# CH32H417 register map
Vendor: WCH Ltd.; File version: 1.2
Registers are 32-bit, read-write, reset 0x0 unless marked. A register's access mark holds for its fields unless they carry their own. Offsets are from the block's base; [hi:lo] are bit positions; lines under a group give offsets from that group; 'fields as' and 'values as' point back to an identical list.

## DFSDM — Digital filter for sigma delta modulators
Base 0x40017000
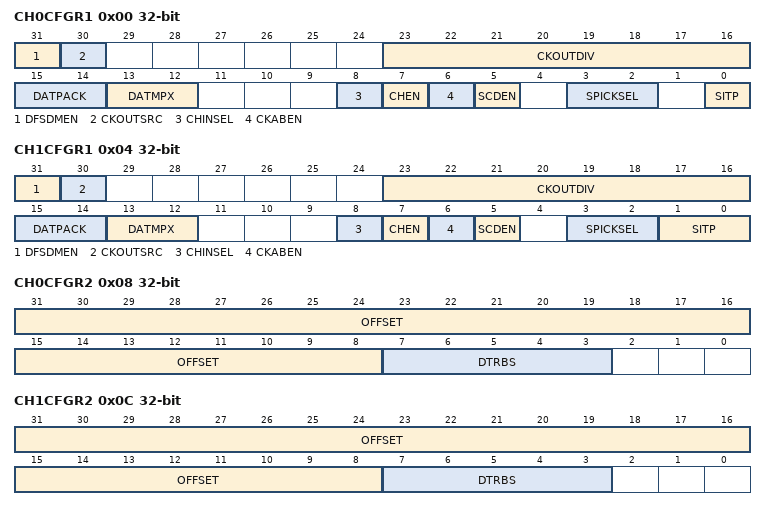
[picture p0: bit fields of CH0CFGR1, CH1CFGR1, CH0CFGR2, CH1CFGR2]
0x00 CH0CFGR1 — channel configuration 0 register
  [31] DFSDMEN — The DFSDM interface is globally enabled
  [30] CKOUTSRC — Output Serial Clock Source Selection
  [23:16] CKOUTDIV — Output Serial Clock Divider
  [15:14] DATPACK — R32_DFSDM_CHyDATINR register data encapsulation mode
  [13:12] DATMPX — Channel 0 Input Data Multiplexer
  [8] CHINSEL — Channel Input Selection
  [7] CHEN — Channel 0 enables
  [6] CKABEN — Channel 0 Clock Missing Detector Enables
  [5] SCDEN — Channel 0 Short Circuit Detector Enables
  [3:2] SPICKSEL — Channel 0 SPI Clock Selection
  [0] SITP — Channel 0 Serial Interface Type
0x04 CH1CFGR1 — channel configuration 1 register
  [31] DFSDMEN — The DFSDM interface is globally enabled
  [30] CKOUTSRC — Output Serial Clock Source Selection
  [23:16] CKOUTDIV — Output Serial Clock Divider
  [15:14] DATPACK — R32_DFSDM_CHyDATINR register data encapsulation mode
  [13:12] DATMPX — Channel 1 Input Data Multiplexer
  [8] CHINSEL — Channel Input Selection
  [7] CHEN — Channel 1 enables
  [6] CKABEN — Channel 1 Clock Missing Detector Enables
  [5] SCDEN — Channel 1 Short Circuit Detector Enables
  [3:2] SPICKSEL — Channel 1 SPI Clock Selection
  [1:0] SITP — Channel 1 Serial Interface Type
0x08 CH0CFGR2 — channel configuration 0 register
  [31:8] OFFSET — Channel 0 24-bit calibration offset
  [7:3] DTRBS — Channel 0 data right shift
0x0C CH1CFGR2 — channel configuration 1 register
  [31:8] OFFSET — Channel 1 24-bit calibration offset
  [7:3] DTRBS — Channel 1 data right shift
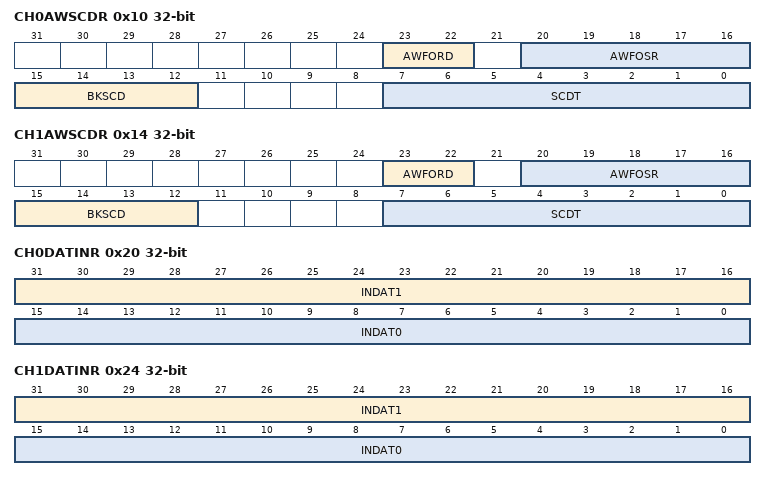
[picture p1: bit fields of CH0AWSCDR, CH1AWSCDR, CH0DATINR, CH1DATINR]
0x10 CH0AWSCDR — analog watchdog and short-circuit detector register
  [23:22] AWFORD — Channel 0 analog watchdog Sinc filter order
  [20:16] AWFOSR — Channel 0 analog watchdog filter oversampling rate
  [15:12] BKSCD — Channel 0 Short Circuit Detector Open Signal Distribution
  [7:0] SCDT — Short Circuit Detector Threshold for Channel 0
0x14 CH1AWSCDR — analog watchdog and short-circuit detector register
  [23:22] AWFORD — Channel 1 analog watchdog Sinc filter order
  [20:16] AWFOSR — Channel 1 analog watchdog filter oversampling rate
  [15:12] BKSCD — Channel 1 Short Circuit Detector Open Signal Distribution
  [7:0] SCDT — Short Circuit Detector Threshold for Channel 1
0x18 CH0WDATR — channel watchdog filter data register
  [15:0] WDATA — Enter channel 0 watchdog data
0x1C CH1WDATR — channel watchdog filter data register
  [15:0] WDATA — Enter channel 1 watchdog data
0x20 CH0DATINR — channel data input register
  [31:16] INDAT1 — Input data for channel y or channel y+1
  [15:0] INDAT0 — Channel Y Input Data
0x24 CH1DATINR — channel data input register
  [31:16] INDAT1 — Input data for channel 1 or channel 2
  [15:0] INDAT0 — Channel 1 Input Data
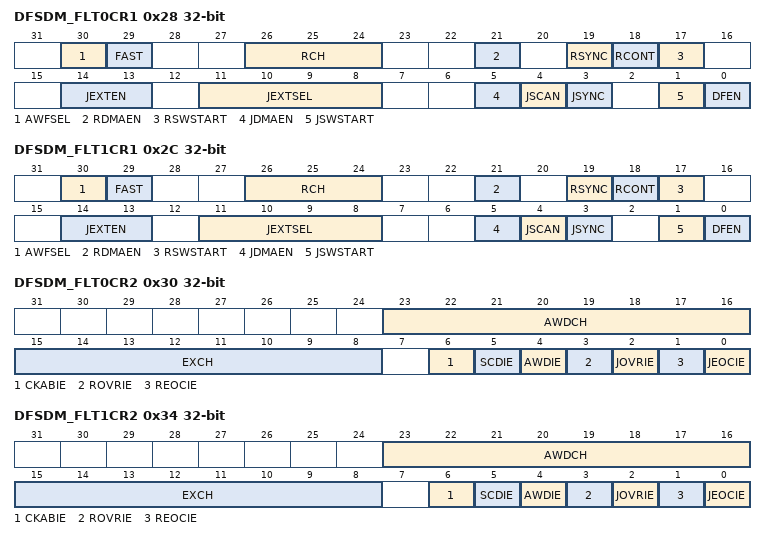
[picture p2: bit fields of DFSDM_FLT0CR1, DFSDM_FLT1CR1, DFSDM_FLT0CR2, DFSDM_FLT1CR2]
0x28 DFSDM_FLT0CR1 — control register 1
  [30] AWFSEL — Analog watchdog fast mode select
  [29] FAST — Fast conversion mode selection for regular conversions
  [26:24] RCH — Regular channel selection
  [21] RDMAEN — DMA channel enabled to read data for the regular conversion
  [19] RSYNC — Launch regular conversion synchronously with DFSDM0
  [18] RCONT — Continuous mode selection for regular conversions
  [17] RSWSTART — Software start of a conversion on the regular channel
  [14:13] JEXTEN — Trigger enable and trigger edge selection for injected conversions
  [11:8] JEXTSEL — Trigger signal selection for launching injected conversions
  [5] JDMAEN — DMA channel enabled to read data for the injected channel group
  [4] JSCAN — Scanning conversion mode for injected conversions
  [3] JSYNC — Launch an injected conversion synchronously with the DFSDM0 JSWSTART trigger
  [1] JSWSTART — Start a conversion of the injected group of channels
  [0] DFEN — DFSDM enable
0x2C DFSDM_FLT1CR1 — control register 1
  fields as DFSDM_FLT0CR1
0x30 DFSDM_FLT0CR2 — control register 2
  [23:16] AWDCH — Analog watchdog channel selection
  [15:8] EXCH — Extremes detector channel selection
  [6] CKABIE — Clock absence interrupt enable
  [5] SCDIE — Short-circuit detector interrupt enable
  [4] AWDIE — Analog watchdog interrupt enable
  [3] ROVRIE — Regular data overrun interrupt enable
  [2] JOVRIE — Injected data overrun interrupt enable
  [1] REOCIE — Regular end of conversion interrupt enable
  [0] JEOCIE — Injected end of conversion interrupt enable
0x34 DFSDM_FLT1CR2 — control register 2
  fields as DFSDM_FLT0CR2
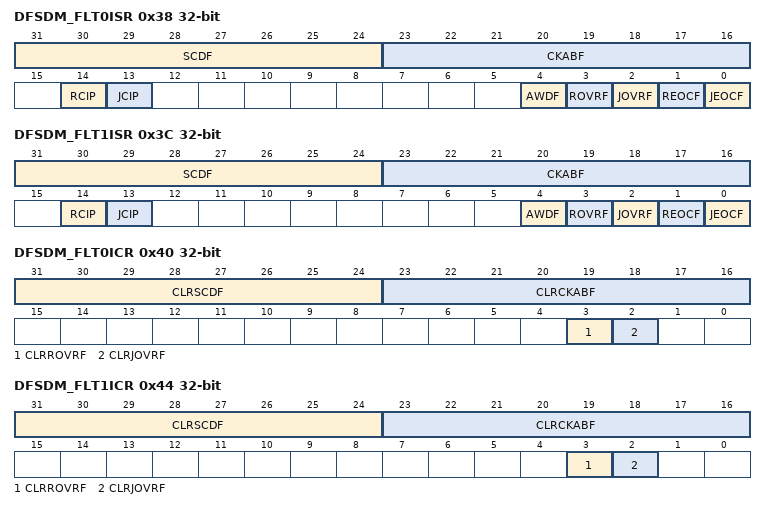
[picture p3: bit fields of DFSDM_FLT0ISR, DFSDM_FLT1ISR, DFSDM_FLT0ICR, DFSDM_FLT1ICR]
0x38 DFSDM_FLT0ISR ro — interrupt and status register
  [31:24] SCDF — short-circuit detector flag
  [23:16] CKABF — Clock absence flag
  [14] RCIP — Regular conversion in progress status
  [13] JCIP — Injected conversion in progress status
  [4] AWDF — Analog watchdog
  [3] ROVRF — Regular conversion overrun flag
  [2] JOVRF — Injected conversion overrun flag
  [1] REOCF — End of regular conversion flag
  [0] JEOCF — End of injected conversion flag
0x3C DFSDM_FLT1ISR ro — interrupt and status register
  fields as DFSDM_FLT0ISR
0x40 DFSDM_FLT0ICR — interrupt flag clear register
  [31:24] CLRSCDF — Clear the short-circuit detector flag
  [23:16] CLRCKABF — Clear the clock absence flag
  [3] CLRROVRF — Clear the regular conversion overrun flag
  [2] CLRJOVRF — Clear the injected conversion overrun flag
0x44 DFSDM_FLT1ICR — interrupt flag clear register
  fields as DFSDM_FLT0ICR
0x48 DFSDM_FLT0JCHGR reset 0x1 — injected channel group selection register
  [1:0] JCHG — Injected channel group selection
0x4C DFSDM_FLT1JCHGR reset 0x1 — injected channel group selection register
  [1:0] JCHG — Injected channel group selection
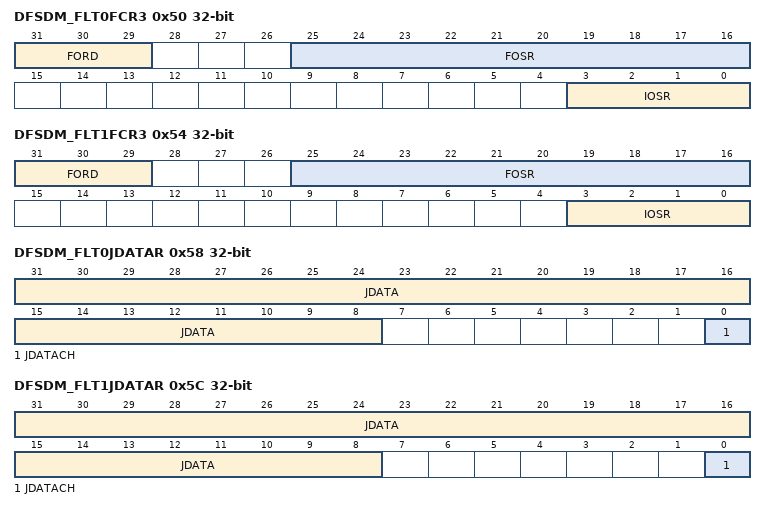
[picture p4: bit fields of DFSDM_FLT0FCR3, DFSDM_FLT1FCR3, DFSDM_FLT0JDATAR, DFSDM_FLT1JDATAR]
0x50 DFSDM_FLT0FCR3 access per field — control register 3
  [31:29] FORD ro — Sinc Filter Order
  [25:16] FOSR rw — Sinc filter oversampling rate
  [3:0] IOSR rw — The integrator oversampling rate is 2 to the power of IOSR
0x54 DFSDM_FLT1FCR3 access per field — control register 3
  fields as DFSDM_FLT0FCR3
0x58 DFSDM_FLT0JDATAR ro — data register for injected group
  [31:8] JDATA — Injected group conversion data
  [0] JDATACH — Injected channel most recently converted
0x5C DFSDM_FLT1JDATAR ro — data register for injected group
  fields as DFSDM_FLT0JDATAR
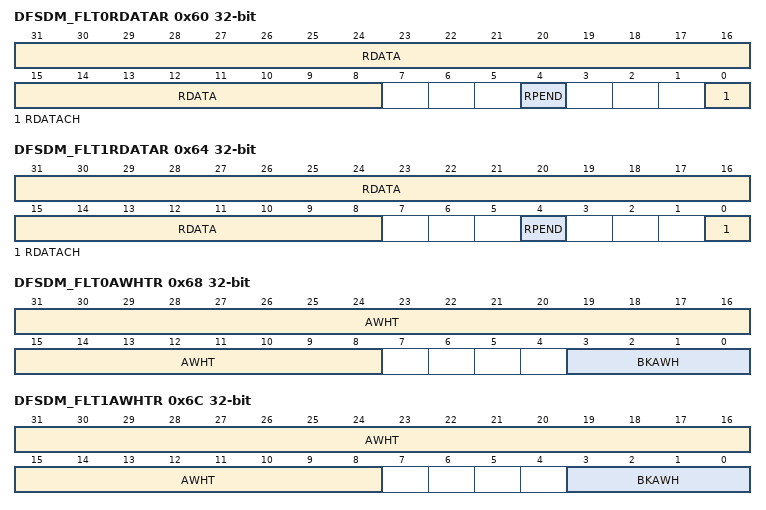
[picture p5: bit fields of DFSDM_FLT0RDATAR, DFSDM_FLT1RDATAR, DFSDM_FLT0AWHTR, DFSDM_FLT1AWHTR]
0x60 DFSDM_FLT0RDATAR ro — data register for the regular channel
  [31:8] RDATA — Regular channel conversion data
  [4] RPEND — Regular channel pending data
  [0] RDATACH — Regular channel most recently converted
0x64 DFSDM_FLT1RDATAR ro — data register for the regular channel
  fields as DFSDM_FLT0RDATAR
0x68 DFSDM_FLT0AWHTR — analog watchdog high threshold register
  [31:8] AWHT — Analog watchdog high threshold
  [3:0] BKAWH — Break signal assignment to analog watchdog high threshold event
0x6C DFSDM_FLT1AWHTR — analog watchdog high threshold register
  fields as DFSDM_FLT0AWHTR
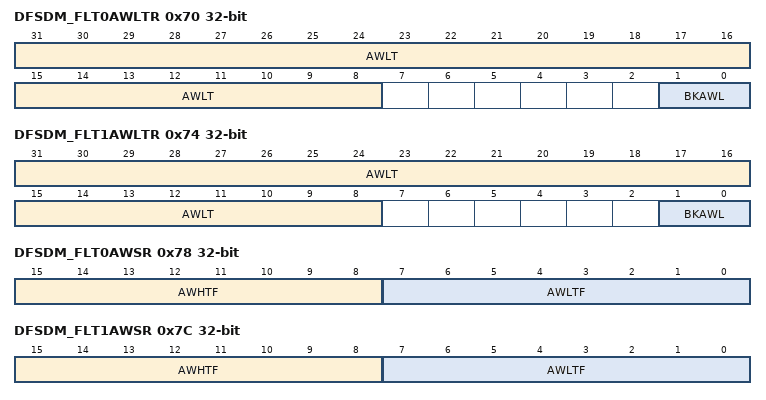
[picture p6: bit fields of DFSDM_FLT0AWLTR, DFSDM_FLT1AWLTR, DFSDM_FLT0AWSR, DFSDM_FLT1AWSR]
0x70 DFSDM_FLT0AWLTR — analog watchdog low threshold register
  [31:8] AWLT — Analog watchdog low threshold
  [1:0] BKAWL — Break signal assignment to analog watchdog low threshold event
0x74 DFSDM_FLT1AWLTR — analog watchdog low threshold register
  fields as DFSDM_FLT0AWLTR
0x78 DFSDM_FLT0AWSR ro — analog watchdog status register
  [15:8] AWHTF — Analog watchdog high threshold flag
  [7:0] AWLTF — Analog watchdog low threshold flag
0x7C DFSDM_FLT1AWSR ro — analog watchdog status register
  fields as DFSDM_FLT0AWSR
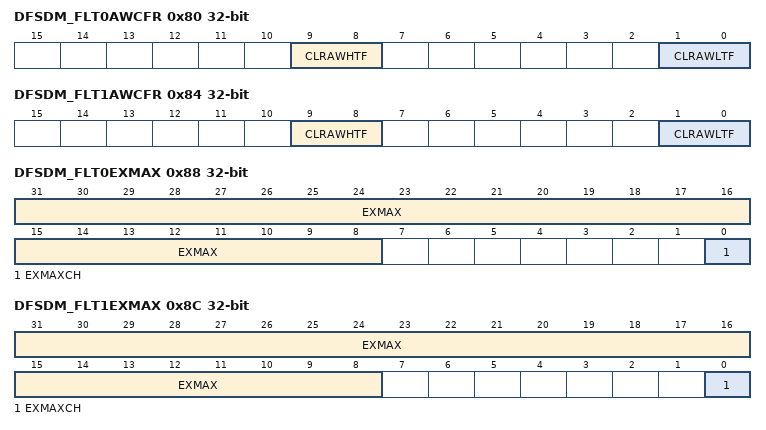
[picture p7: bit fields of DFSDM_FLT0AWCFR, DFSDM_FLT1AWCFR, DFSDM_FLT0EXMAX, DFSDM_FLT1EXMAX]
0x80 DFSDM_FLT0AWCFR — analog watchdog clear flag register
  [9:8] CLRAWHTF — Clear the analog watchdog high threshold flag
  [1:0] CLRAWLTF — Clear the analog watchdog low threshold flag
0x84 DFSDM_FLT1AWCFR — analog watchdog clear flag register
  fields as DFSDM_FLT0AWCFR
0x88 DFSDM_FLT0EXMAX ro — Extremes detector maximum register
  [31:8] EXMAX — Extremes detector maximum value
  [0] EXMAXCH — Extremes detector maximum data channel
0x8C DFSDM_FLT1EXMAX ro — Extremes detector maximum register
  fields as DFSDM_FLT0EXMAX
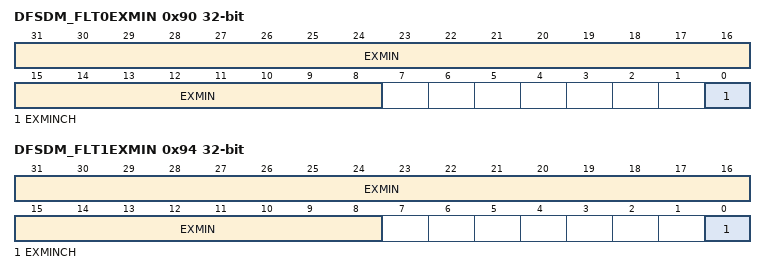
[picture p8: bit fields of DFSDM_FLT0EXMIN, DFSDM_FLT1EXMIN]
0x90 DFSDM_FLT0EXMIN ro — Extremes detector minimum register
  [31:8] EXMIN
  [0] EXMINCH — Extremes detector minimum data channel
0x94 DFSDM_FLT1EXMIN ro — Extremes detector minimum register
  [31:8] EXMIN
  [0] EXMINCH — Extremes detector minimum data channel
0x98 DFSDM_FLT0CNVTIMR ro — conversion timer register
  [31:4] CNVCNT — 28-bit timer counting conversion time t = CNVCNT[27:0] / fDFSDM_CKIN
0x9C DFSDM_FLT1CNVTIMR ro — conversion timer register
  fields as DFSDM_FLT0CNVTIMR
